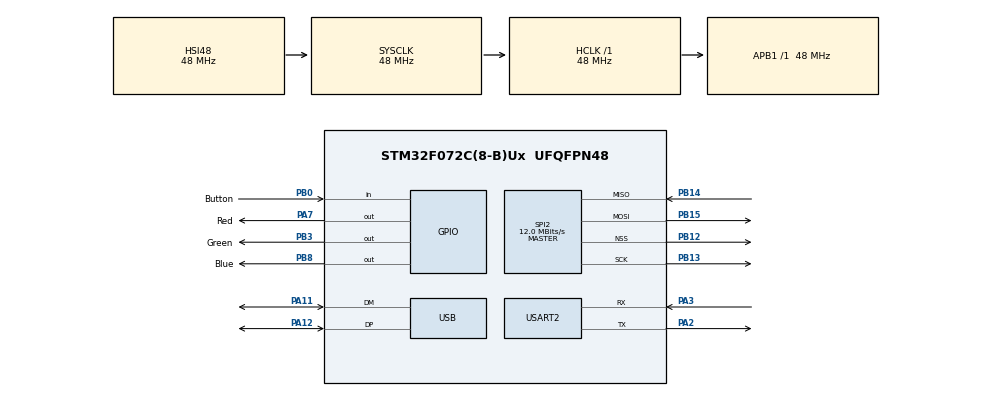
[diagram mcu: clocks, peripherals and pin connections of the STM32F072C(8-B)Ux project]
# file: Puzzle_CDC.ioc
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Mcu.Family=STM32F0
Mcu.Name=STM32F072C(8-B)Ux
Mcu.Package=UFQFPN48
NVIC.USB_IRQn=true\:0\:0\:false\:false\:true\:true
PA11.Mode=Device
PA11.Signal=USB_DM
PA12.Mode=Device
PA12.Signal=USB_DP
PA13.Mode=Serial_Wire
PA13.Signal=SYS_SWDIO
PA14.Mode=Serial_Wire
PA14.Signal=SYS_SWCLK
PA2.Mode=Asynchronous
PA2.Signal=USART2_TX
PA3.Mode=Asynchronous
PA3.Signal=USART2_RX
PA7.GPIO_Label=Red
PA7.Signal=GPIO_Output
PB0.GPIO_Label=Button
PB0.Signal=GPIO_Input
PB12.Mode=NSS_Signal_Hard_Output
PB12.Signal=SPI2_NSS
PB13.Mode=Full_Duplex_Master
PB13.Signal=SPI2_SCK
PB14.Mode=Full_Duplex_Master
PB14.Signal=SPI2_MISO
PB15.Mode=Full_Duplex_Master
PB15.Signal=SPI2_MOSI
PB3.GPIO_Label=Green
PB3.Signal=GPIO_Output
PB8.GPIO_Label=Blue
PB8.Signal=GPIO_Output
ProjectManager.HeapSize=0x200
ProjectManager.StackSize=0x400
ProjectManager.TargetToolchain=MDK-ARM V5
RCC.AHBFreq_Value=48000000
RCC.APB1Freq_Value=48000000
RCC.APB1TimFreq_Value=48000000
RCC.HCLKFreq_Value=48000000
RCC.SYSCLKFreq_VALUE=48000000
RCC.SYSCLKSource=RCC_SYSCLKSOURCE_HSI48
SPI2.BaudRatePrescaler=SPI_BAUDRATEPRESCALER_4
SPI2.CalculateBaudRate=12.0 MBits/s
SPI2.Direction=SPI_DIRECTION_2LINES
SPI2.Mode=SPI_MODE_MASTER
SPI2.VirtualNSS=VM_NSSHARD
SPI2.VirtualType=VM_MASTER
USART2.VirtualMode-Asynchronous=VM_ASYNC
USB.low_power_enable=ENABLE
USB_DEVICE.CLASS_NAME_FS=CDC
USB_DEVICE.VirtualMode=Cdc
USB_DEVICE.VirtualModeFS=Cdc_FS
VP_FATFS_VS_Generic.Mode=User_defined
VP_USB_DEVICE_VS_USB_DEVICE_CDC_FS.Mode=CDC_FS
board=Puzzle_CDC

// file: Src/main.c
/**
  ******************************************************************************
  * @file           : main.c
  * @brief          : Main program body
  ******************************************************************************
  * This notice applies to any and all portions of this file
  * that are not between comment pairs USER CODE BEGIN and
  * USER CODE END. Other portions of this file, whether
  * inserted by the user or by software development tools
  * are owned by their respective copyright owners.
  *
  * Copyright (c) 2018 STMicroelectronics International N.V.
  * All rights reserved.
  *
  * Redistribution and use in source and binary forms, with or without
  * modification, are permitted, provided that the following conditions are met:
  *
  * 1. Redistribution of source code must retain the above copyright notice,
  *    this list of conditions and the following disclaimer.
  * 2. Redistributions in binary form must reproduce the above copyright notice,
  *    this list of conditions and the following disclaimer in the documentation
  *    and/or other materials provided with the distribution.
  * 3. Neither the name of STMicroelectronics nor the names of other
  *    contributors to this software may be used to endorse or promote products
  *    derived from this software without specific written permission.
  * 4. This software, including modifications and/or derivative works of this
  *    software, must execute solely and exclusively on microcontroller or
  *    microprocessor devices manufactured by or for STMicroelectronics.
  * 5. Redistribution and use of this software other than as permitted under
  *    this license is void and will automatically terminate your rights under
  *    this license.
  *
  * THIS SOFTWARE IS PROVIDED BY STMICROELECTRONICS AND CONTRIBUTORS "AS IS"
  * AND ANY EXPRESS, IMPLIED OR STATUTORY WARRANTIES, INCLUDING, BUT NOT
  * LIMITED TO, THE IMPLIED WARRANTIES OF MERCHANTABILITY, FITNESS FOR A
  * PARTICULAR PURPOSE AND NON-INFRINGEMENT OF THIRD PARTY INTELLECTUAL PROPERTY
  * RIGHTS ARE DISCLAIMED TO THE FULLEST EXTENT PERMITTED BY LAW. IN NO EVENT
  * SHALL STMICROELECTRONICS OR CONTRIBUTORS BE LIABLE FOR ANY DIRECT, INDIRECT,
  * INCIDENTAL, SPECIAL, EXEMPLARY, OR CONSEQUENTIAL DAMAGES (INCLUDING, BUT NOT
  * LIMITED TO, PROCUREMENT OF SUBSTITUTE GOODS OR SERVICES; LOSS OF USE, DATA,
  * OR PROFITS; OR BUSINESS INTERRUPTION) HOWEVER CAUSED AND ON ANY THEORY OF
  * LIABILITY, WHETHER IN CONTRACT, STRICT LIABILITY, OR TORT (INCLUDING
  * NEGLIGENCE OR OTHERWISE) ARISING IN ANY WAY OUT OF THE USE OF THIS SOFTWARE,
  * EVEN IF ADVISED OF THE POSSIBILITY OF SUCH DAMAGE.
  *
  ******************************************************************************
  */
#include "main.h"
#include "stm32f0xx_hal.h"
#include "fatfs.h"
#include "usb_device.h"
#include "spi_nor_flash.h"

SPI_HandleTypeDef hspi2;

UART_HandleTypeDef huart2;

/* USER CODE BEGIN PV */
/* Private variables ---------------------------------------------------------*/

/* USER CODE END PV */

void SystemClock_Config(void);
static void MX_GPIO_Init(void);
static void MX_USART2_UART_Init(void);
static void MX_SPI2_Init(void);

/* USER CODE BEGIN PFP */
/* Private function prototypes -----------------------------------------------*/

/* USER CODE END PFP */

/* USER CODE BEGIN 0 */
uint8_t led_pwm[] = {0,0,0};
uint16_t led_accum[] = {0,0,0};
uint32_t key_timer;
uint8_t mode;

uint8_t colors[6][3]={
	{ 255, 0,   0   },//red
	{ 0,   255, 0   },//green
	{ 0,   0,   255 },//blue
	{ 255, 255, 0   },//yellow
	{ 255, 0,   255 },//magenta
	{ 0,   255, 255 },//cyan

};

uint8_t get_button(void){

	return GPIOB->IDR & (1<<0);
}

void led_on(uint8_t led){

	if(led == 0){ GPIOA->ODR &= ~(1 << 7); }
	if(led == 1){ GPIOB->ODR &= ~(1 << 3); }
	if(led == 2){ GPIOB->ODR &= ~(1 << 8); }
}

void led_off(uint8_t led){

	if(led == 0){ GPIOA->ODR |= (1 << 7); }
	if(led == 1){ GPIOB->ODR |= (1 << 3); }
	if(led == 2){ GPIOB->ODR |= (1 << 8); }
}

/* USER CODE END 0 */

int main(void)
{

  /* MCU Configuration----------------------------------------------------------*/

  /* Reset of all peripherals, Initializes the Flash interface and the Systick. */
  HAL_Init();

  /* Configure the system clock */
  SystemClock_Config();

  /* Initialize all configured peripherals */
  MX_GPIO_Init();
  MX_USART2_UART_Init();
  MX_FATFS_Init();
  MX_SPI2_Init();
  MX_USB_DEVICE_Init();
  /* USER CODE BEGIN 2 */

	printf("Dia duit!\n");

init_spi_flash();

   // try some flash accesses
   __ALIGN_BEGIN uint8_t txSpiBuf[16];
   __ALIGN_BEGIN uint8_t rxSpiBuf[16];
   txSpiBuf[0] = CMD_READ_STATUS_REGISTER;
   HAL_SPI_TransmitReceive( &hspi, txSpiBuf, rxSpiBuf, 2, 10);SPI2->CR1 &= ~SPI_CR1_SPE;

   printf("Status Reg:%02x\n", rxSpiBuf[1]);

   txSpiBuf[0] = CMD_READ_ID;
   HAL_SPI_TransmitReceive( &hspi, txSpiBuf, rxSpiBuf, 16, 10);SPI2->CR1 &= ~SPI_CR1_SPE;

   printf("ID        :");
   for(int i = 1; i < 16; i++){

      printf("%02x",rxSpiBuf[i]);

   }printf("\n");SPI2->CR1 &= ~SPI_CR1_SPE;

  /* USER CODE END 2 */

  /* Infinite loop */
  while (1)
  {

  }

}

void SystemClock_Config(void)
{

  RCC_OscInitTypeDef RCC_OscInitStruct;
  RCC_ClkInitTypeDef RCC_ClkInitStruct;
  RCC_PeriphCLKInitTypeDef PeriphClkInit;

    /**Initializes the CPU, AHB and APB busses clocks
    */
  RCC_OscInitStruct.OscillatorType = RCC_OSCILLATORTYPE_HSI48;
  RCC_OscInitStruct.HSI48State = RCC_HSI48_ON;
  RCC_OscInitStruct.PLL.PLLState = RCC_PLL_NONE;
  if (HAL_RCC_OscConfig(&RCC_OscInitStruct) != HAL_OK)
  {
    _Error_Handler(__FILE__, __LINE__);
  }

    /**Initializes the CPU, AHB and APB busses clocks
    */
  RCC_ClkInitStruct.ClockType = RCC_CLOCKTYPE_HCLK|RCC_CLOCKTYPE_SYSCLK
                              |RCC_CLOCKTYPE_PCLK1;
  RCC_ClkInitStruct.SYSCLKSource = RCC_SYSCLKSOURCE_HSI48;
  RCC_ClkInitStruct.AHBCLKDivider = RCC_SYSCLK_DIV1;
  RCC_ClkInitStruct.APB1CLKDivider = RCC_HCLK_DIV1;

  if (HAL_RCC_ClockConfig(&RCC_ClkInitStruct, FLASH_LATENCY_1) != HAL_OK)
  {
    _Error_Handler(__FILE__, __LINE__);
  }

  PeriphClkInit.PeriphClockSelection = RCC_PERIPHCLK_USB|RCC_PERIPHCLK_USART2;
  PeriphClkInit.Usart2ClockSelection = RCC_USART2CLKSOURCE_PCLK1;
  PeriphClkInit.UsbClockSelection = RCC_USBCLKSOURCE_HSI48;

  if (HAL_RCCEx_PeriphCLKConfig(&PeriphClkInit) != HAL_OK)
  {
    _Error_Handler(__FILE__, __LINE__);
  }

    /**Configure the Systick interrupt time
    */
  HAL_SYSTICK_Config(HAL_RCC_GetHCLKFreq()/1000);

    /**Configure the Systick
    */
  HAL_SYSTICK_CLKSourceConfig(SYSTICK_CLKSOURCE_HCLK);

  /* SysTick_IRQn interrupt configuration */
  HAL_NVIC_SetPriority(SysTick_IRQn, 0, 0);
}

/* SPI2 init function */
static void MX_SPI2_Init(void)
{

  /* SPI2 parameter configuration*/
  hspi2.Instance = SPI2;
  hspi2.Init.Mode = SPI_MODE_MASTER;
  hspi2.Init.Direction = SPI_DIRECTION_2LINES;
  hspi2.Init.DataSize = SPI_DATASIZE_4BIT;
  hspi2.Init.CLKPolarity = SPI_POLARITY_LOW;
  hspi2.Init.CLKPhase = SPI_PHASE_1EDGE;
  hspi2.Init.NSS = SPI_NSS_HARD_OUTPUT;
  hspi2.Init.BaudRatePrescaler = SPI_BAUDRATEPRESCALER_4;
  hspi2.Init.FirstBit = SPI_FIRSTBIT_MSB;
  hspi2.Init.TIMode = SPI_TIMODE_DISABLE;
  hspi2.Init.CRCCalculation = SPI_CRCCALCULATION_DISABLE;
  hspi2.Init.CRCPolynomial = 7;
  hspi2.Init.CRCLength = SPI_CRC_LENGTH_DATASIZE;
  hspi2.Init.NSSPMode = SPI_NSS_PULSE_ENABLE;
  if (HAL_SPI_Init(&hspi2) != HAL_OK)
  {
    _Error_Handler(__FILE__, __LINE__);
  }

}

/* USART2 init function */
static void MX_USART2_UART_Init(void)
{

  huart2.Instance = USART2;
  huart2.Init.BaudRate = 38400;
  huart2.Init.WordLength = UART_WORDLENGTH_7B;
  huart2.Init.StopBits = UART_STOPBITS_1;
  huart2.Init.Parity = UART_PARITY_NONE;
  huart2.Init.Mode = UART_MODE_TX_RX;
  huart2.Init.HwFlowCtl = UART_HWCONTROL_NONE;
  huart2.Init.OverSampling = UART_OVERSAMPLING_16;
  huart2.Init.OneBitSampling = UART_ONE_BIT_SAMPLE_DISABLE;
  huart2.AdvancedInit.AdvFeatureInit = UART_ADVFEATURE_NO_INIT;
  if (HAL_UART_Init(&huart2) != HAL_OK)
  {
    _Error_Handler(__FILE__, __LINE__);
  }

}

/** Configure pins as
        * Analog
        * Input
        * Output
        * EVENT_OUT
        * EXTI
*/
static void MX_GPIO_Init(void)
{

  GPIO_InitTypeDef GPIO_InitStruct;

  /* GPIO Ports Clock Enable */
  __HAL_RCC_GPIOA_CLK_ENABLE();
  __HAL_RCC_GPIOB_CLK_ENABLE();

  /*Configure GPIO pin Output Level */
  HAL_GPIO_WritePin(Red_GPIO_Port, Red_Pin, GPIO_PIN_RESET);

  /*Configure GPIO pin Output Level */
  HAL_GPIO_WritePin(GPIOB, Green_Pin|Blue_Pin, GPIO_PIN_RESET);

  /*Configure GPIO pin : Red_Pin */
  GPIO_InitStruct.Pin = Red_Pin;
  GPIO_InitStruct.Mode = GPIO_MODE_OUTPUT_PP;
  GPIO_InitStruct.Pull = GPIO_NOPULL;
  GPIO_InitStruct.Speed = GPIO_SPEED_FREQ_LOW;
  HAL_GPIO_Init(Red_GPIO_Port, &GPIO_InitStruct);

  /*Configure GPIO pin : Button_Pin */
  GPIO_InitStruct.Pin = Button_Pin;
  GPIO_InitStruct.Mode = GPIO_MODE_INPUT;
  GPIO_InitStruct.Pull = GPIO_NOPULL;
  HAL_GPIO_Init(Button_GPIO_Port, &GPIO_InitStruct);

  /*Configure GPIO pins : Green_Pin Blue_Pin */
  GPIO_InitStruct.Pin = Green_Pin|Blue_Pin;
  GPIO_InitStruct.Mode = GPIO_MODE_OUTPUT_PP;
  GPIO_InitStruct.Pull = GPIO_NOPULL;
  GPIO_InitStruct.Speed = GPIO_SPEED_FREQ_LOW;
  HAL_GPIO_Init(GPIOB, &GPIO_InitStruct);

	  /*Configure GPIO pins : Green_Pin Blue_Pin */
  GPIO_InitStruct.Pin = GPIO_PIN_11 | GPIO_PIN_12;
  GPIO_InitStruct.Mode = GPIO_MODE_AF_PP;
	GPIO_InitStruct.Alternate = GPIO_AF2_USB;
  GPIO_InitStruct.Pull = GPIO_NOPULL;
  GPIO_InitStruct.Speed = GPIO_SPEED_FREQ_HIGH;
  HAL_GPIO_Init(GPIOB, &GPIO_InitStruct);

}

/* USER CODE BEGIN 4 */

void HAL_SYSTICK_Callback(void)
{

if( get_button() == 0){

		key_timer++;

	}

	for(int i = 0; i< 3; i++){

		led_accum[i] += led_pwm[i];
		if( led_accum[i] > 256 ){
			led_accum[i] -= 256;
			led_on(i);
		}else{
			led_off(i);
		}
	}

}

/* USER CODE END 4 */

void _Error_Handler(char *file, int line)
{
  while(1)
  {
  }
}

/************************ (C) COPYRIGHT STMicroelectronics *****END OF FILE****/
